# f2838x_mcbsp_regs register map
Vendor: Texas Instruments
Peripheral module from a debugger description file (folder C2000).
Address unit: 16 bits
Registers are 16-bit, read-write, no defined reset value unless marked. A register's access mark holds for its fields unless they carry their own. Offsets are as the file gives them; lines under a group give offsets from that group; [hi:lo] are bit positions; {n}, {i} and the like mark numbered series; 'fields as' and 'values as' point back to an identical list; <NAME> marks a mode.

## McBSP_REGS — McBSP Registers
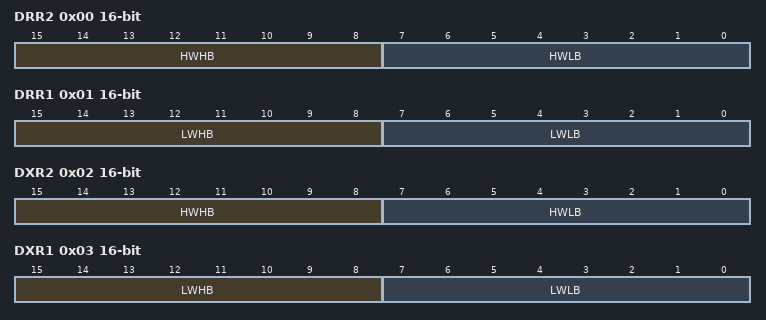
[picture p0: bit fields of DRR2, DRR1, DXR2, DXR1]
0x00 DRR2 — Data receive register bits 31-16
  [15:8] HWHB — High word high byte
  [7:0] HWLB — High word low byte
0x01 DRR1 — Data receive register bits 15-0
  [15:8] LWHB — Low word high byte
  [7:0] LWLB — Low word low byte
0x02 DXR2 — Data transmit register bits 31-16
  [15:8] HWHB — High word high byte
  [7:0] HWLB — High word low byte
0x03 DXR1 — Data transmit register bits 15-0
  [15:8] LWHB — Low word high byte
  [7:0] LWLB — Low word low byte
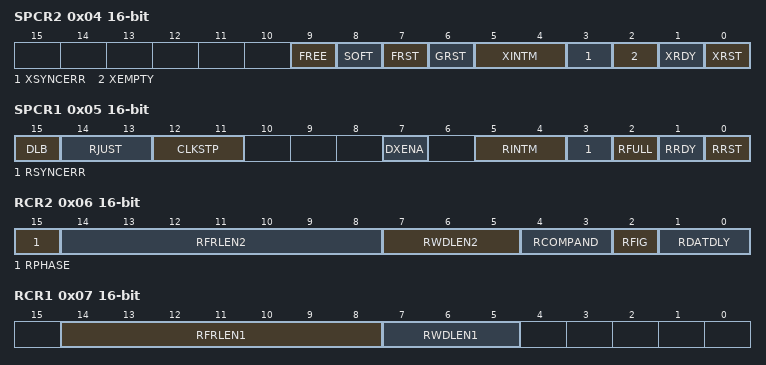
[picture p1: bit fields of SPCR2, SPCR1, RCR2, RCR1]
0x04 SPCR2 access per field — Serial port control register 2
  [9] FREE rw — FREE bit
  [8] SOFT rw — SOFT bit
  [7] FRST rw — Frame sync logic reset
  [6] GRST rw — Sample rate generator reset
  [5:4] XINTM rw — Transmit Interupt mode bits
  [3] XSYNCERR rw — Transmit sync error INT flag
  [2] XEMPTY ro — Transmitter empty
  [1] XRDY ro — Transmitter ready
  [0] XRST rw — Transmitter reset
0x05 SPCR1 access per field — Serial port control register 1
  [15] DLB rw — Digital loopback
  [14:13] RJUST rw — Rx sign extension and justification mode
  [12:11] CLKSTP rw — Clock stop mode
  [7] DXENA rw — DX delay enable
  [5:4] RINTM rw — Receive Interupt mode bits
  [3] RSYNCERR rw — Receive sync error INT flag
  [2] RFULL ro — Receiver full
  [1] RRDY ro — Receiver ready
  [0] RRST rw — Receiver reset
0x06 RCR2 — Receive Control register 2
  [15] RPHASE — Receive Phase
  [14:8] RFRLEN2 — Receive Frame length 2
  [7:5] RWDLEN2 — Receive word length 2
  [4:3] RCOMPAND — Receive Companding Mode selects
  [2] RFIG — Receive frame sync ignore
  [1:0] RDATDLY — Receive data delay
0x07 RCR1 — Receive Control register 1
  [14:8] RFRLEN1 — Receive Frame length 1
  [7:5] RWDLEN1 — Receive word length 1
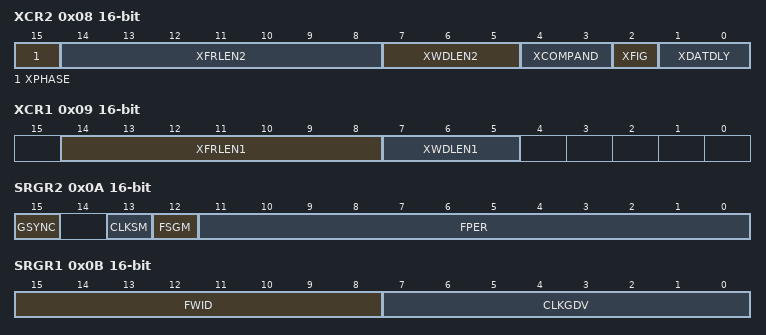
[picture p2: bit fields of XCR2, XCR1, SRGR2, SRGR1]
0x08 XCR2 — Transmit Control register 2
  [15] XPHASE — Transmit Phase
  [14:8] XFRLEN2 — Transmit Frame length 2
  [7:5] XWDLEN2 — Transmit word length 2
  [4:3] XCOMPAND — Transmit Companding Mode selects
  [2] XFIG — Transmit frame sync ignore
  [1:0] XDATDLY — Transmit data delay
0x09 XCR1 — Transmit Control register 1
  [14:8] XFRLEN1 — Transmit Frame length 1
  [7:5] XWDLEN1 — Transmit word length 1
0x0A SRGR2 — Sample rate generator register 2
  [15] GSYNC — CLKG sync
  [13] CLKSM — Sample rate generator mode
  [12] FSGM — Frame sync generator mode
  [11:0] FPER — Frame-sync period
0x0B SRGR1 — Sample rate generator register 1
  [15:8] FWID — Frame width
  [7:0] CLKGDV — CLKG divider
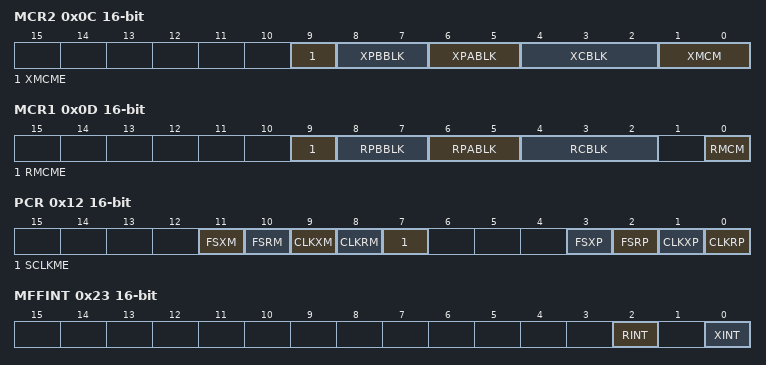
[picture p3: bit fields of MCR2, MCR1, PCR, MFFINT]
0x0C MCR2 access per field — Multi-channel control register 2
  [9] XMCME rw — Transmit Frame length 2
  [8:7] XPBBLK rw — Transmit word length 2
  [6:5] XPABLK rw — Transmit Companding Mode selects
  [4:2] XCBLK ro — Transmit frame sync ignore
  [1:0] XMCM rw — Transmit data delay
0x0D MCR1 access per field — Multi-channel control register 1
  [9] RMCME rw — Receive multi-channel enhance mode
  [8:7] RPBBLK rw — Receive partition B Block
  [6:5] RPABLK rw — Receive partition A Block
  [4:2] RCBLK ro — eceive current block
  [0] RMCM rw — Receive multichannel mode
0x0E RCERA — Receive channel enable partition A
  [15:0] RCEA — Receive channel enable bit.
0x0F RCERB — Receive channel enable partition B
  [15:0] RCEB — Receive channel enable bit.
0x10 XCERA — Transmit channel enable partition A
  [15:0] XCERA — Transmit Channel enable bit
0x11 XCERB — Transmit channel enable partition B
  [15:0] XCERB — Transmit Channel enable bit
0x12 PCR access per field — Pin Control register
  [11] FSXM rw — Transmit Frame Synchronization Mode
  [10] FSRM rw — Receive Frame Synchronization Mode
  [9] CLKXM rw — Transmit Clock Mode.
  [8] CLKRM rw — Receiver Clock Mode
  [7] SCLKME rw — Sample clock mode selection
  [3] FSXP rw — Transmit Frame synchronization polarity
  [2] FSRP ro — Receive Frame synchronization polarity
  [1] CLKXP ro — Transmit clock polarity
  [0] CLKRP rw — Receive Clock polarity
0x13 RCERC — Receive channel enable partition C
  [15:0] RCEC — Receive channel enable bit.
0x14 RCERD — Receive channel enable partition D
  [15:0] RCED — Receive channel enable bit.
0x15 XCERC — Transmit channel enable partition C
  [15:0] XCERC — Transmit Channel enable bit
0x16 XCERD — Transmit channel enable partition D
  [15:0] XCERD — Transmit Channel enable bit
0x17 RCERE — Receive channel enable partition E
  [15:0] RCEE — Receive channel enable bit.
0x18 RCERF — Receive channel enable partition F
  [15:0] RCEF — Receive channel enable bit.
0x19 XCERE — Transmit channel enable partition E
  [15:0] XCERE — Transmit Channel enable bit
0x1A XCERF — Transmit channel enable partition F
  [15:0] XCERF — Transmit Channel enable bit
0x1B RCERG — Receive channel enable partition G
  [15:0] RCEG — Receive channel enable bit.
0x1C RCERH — Receive channel enable partition H
  [15:0] RCEH — Receive channel enable bit.
0x1D XCERG — Transmit channel enable partition G
  [15:0] XCERG — Transmit Channel enable bit
0x1E XCERH — Transmit channel enable partition H
  [15:0] XCERH — Transmit Channel enable bit
0x23 MFFINT — Interrupt enable
  [2] RINT — Enable for transmit Interrupt
  [0] XINT — Enable for Receive Interrupt
